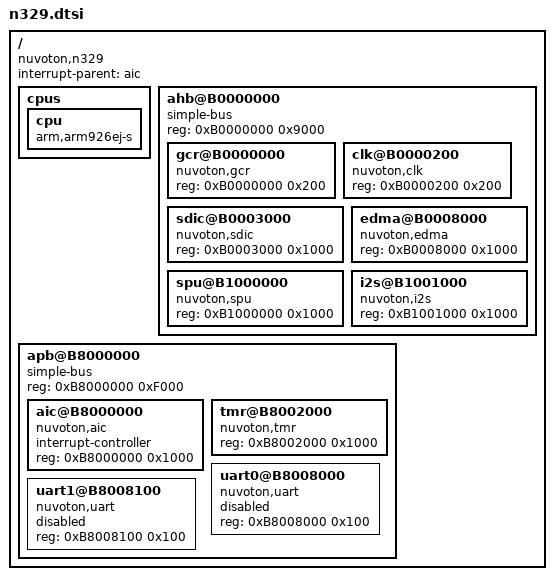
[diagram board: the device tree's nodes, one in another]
/*
 * Copyright (C) 2014 Michael P. Thompson, Inc. All Rights Reserved.
 *
 * This program is free software; you can redistribute it and/or modify
 * it under the terms of the GNU General Public License as published by
 * the Free Software Foundation; either version 2 of the License, or
 * (at your option) any later version.
 *
 * This program is distributed in the hope that it will be useful,
 * but WITHOUT ANY WARRANTY; without even the implied warranty of
 * MERCHANTABILITY or FITNESS FOR A PARTICULAR PURPOSE.  See the
 * GNU General Public License for more details.
 *
 * You should have received a copy of the GNU General Public License along
 * with this program; if not, write to the Free Software Foundation, Inc.,
 * 51 Franklin Street, Fifth Floor, Boston, MA 02110-1301 USA.
 */

#include "skeleton.dtsi"

/ {
	compatible = "nuvoton,n329";

	interrupt-parent = <&aic>;

	cpus {
		#address-cells = <0>;
		#size-cells = <0>;

		cpu {
			compatible = "arm,arm926ej-s";
			device_type = "cpu";
		};
	};

	ahb@B0000000 {
		compatible = "simple-bus";
		#address-cells = <1>;
		#size-cells = <1>;
		reg = <0xB0000000 0x9000>;
		ranges;

		gcr@B0000000 {
			compatible = "nuvoton,gcr";
			reg = <0xB0000000 0x200>;
		};

		clk@B0000200 {
			compatible = "nuvoton,clk";
			reg = <0xB0000200 0x200>;
		};

		sdic@B0003000 {
			compatible = "nuvoton,sdic";
			reg = <0xB0003000 0x1000>;
		};

		edma@B0008000 {
			compatible = "nuvoton,edma";
			reg = <0xB0008000 0x1000>;
		};

		spu@B1000000 {
			compatible = "nuvoton,spu";
			reg = <0xB1000000 0x1000>;
		};

		i2s@B1001000 {
			compatible = "nuvoton,i2s";
			reg = <0xB1001000 0x1000>;
		};
	};

	apb@B8000000 {
		compatible = "simple-bus";
		#address-cells = <1>;
		#size-cells = <1>;
		reg = <0xB8000000 0xF000>;
		ranges;

		aic@B8000000 {
			compatible = "nuvoton,aic";
			interrupt-controller;
			#interrupt-cells = <1>;
			reg = <0xB8000000 0x1000>;
		};

		tmr@B8002000 {
			compatible = "nuvoton,tmr";
			reg = <0xB8002000 0x1000>;
		};

		uart0@B8008000 {
			compatible = "nuvoton,uart";
			reg = <0xB8008000 0x100>;
			status = "disabled";
		};

		uart1@B8008100 {
			compatible = "nuvoton,uart";
			reg = <0xB8008100 0x100>;
			status = "disabled";
		};
	};
};
